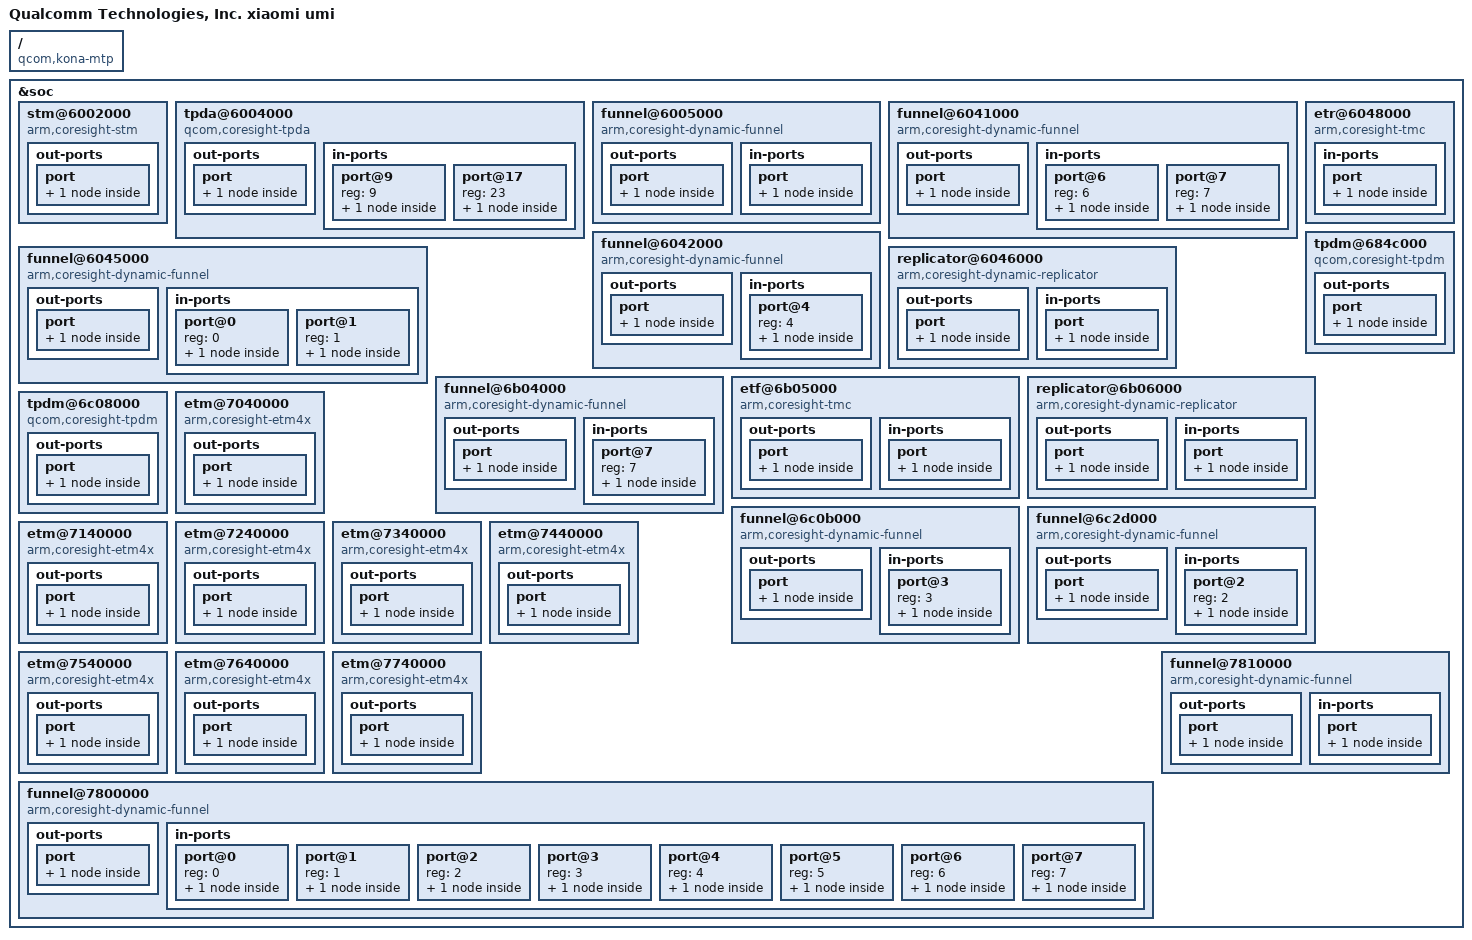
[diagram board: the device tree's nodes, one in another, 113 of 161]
/dts-v1/;
/plugin/;

#include <dt-bindings/clock/qcom,gcc-kona.h>
#include <dt-bindings/clock/qcom,camcc-kona.h>
#include <dt-bindings/clock/qcom,rpmh.h>
#include <dt-bindings/interrupt-controller/arm-gic.h>

#include "umi-sm8250.dtsi"
#include "umi-sm8250-camera-sensor-mtp.dtsi"
/ {
	model = "Qualcomm Technologies, Inc. xiaomi umi";
	compatible = "qcom,kona-mtp", "qcom,kona", "qcom,mtp";
	qcom,board-id = <43 0>;
};

&soc {
	/* CoreSight APSS ETM + funnels + sinks (from upstream sm8250.dtsi) */
	stm@6002000 {
		compatible = "arm,coresight-stm", "arm,primecell";
		reg = <0 0x06002000 0 0x1000>, <0 0x16280000 0 0x180000>;
		reg-names = "stm-base", "stm-stimulus-base";

		clocks = <&aoss_qmp>;
		clock-names = "apb_pclk";

		out-ports {
			port {
				stm_out: endpoint {
					remote-endpoint = <&funnel0_in7>;
				};
			};
		};
	};

	tpda@6004000 {
		compatible = "qcom,coresight-tpda", "arm,primecell";
		reg = <0 0x06004000 0 0x1000>;

		clocks = <&aoss_qmp>;
		clock-names = "apb_pclk";

		out-ports {
			port {
				tpda_out_funnel_qatb: endpoint {
					remote-endpoint = <&funnel_qatb_in_tpda>;
				};
			};
		};

		in-ports {
			#address-cells = <1>;
			#size-cells = <0>;

			port@9 {
				reg = <9>;
				tpda_9_in_tpdm_mm: endpoint {
					remote-endpoint = <&tpdm_mm_out_tpda9>;
				};
			};

			port@17 {
				reg = <23>;
				tpda_23_in_tpdm_prng: endpoint {
					remote-endpoint = <&tpdm_prng_out_tpda_23>;
				};
			};
		};
	};

	funnel@6005000 {
		compatible = "arm,coresight-dynamic-funnel", "arm,primecell";
		reg = <0 0x06005000 0 0x1000>;

		clocks = <&aoss_qmp>;
		clock-names = "apb_pclk";

		out-ports {
			port {
				funnel_qatb_out_funnel_in0: endpoint {
					remote-endpoint = <&funnel_in0_in_funnel_qatb>;
				};
			};
		};

		in-ports {
			port {
				funnel_qatb_in_tpda: endpoint {
					remote-endpoint = <&tpda_out_funnel_qatb>;
				};
			};
		};
	};

	funnel@6041000 {
		compatible = "arm,coresight-dynamic-funnel", "arm,primecell";
		reg = <0 0x06041000 0 0x1000>;

		clocks = <&aoss_qmp>;
		clock-names = "apb_pclk";

		out-ports {
			port {
				funnel_in0_out_funnel_merg: endpoint {
					remote-endpoint = <&funnel_merg_in_funnel_in0>;
				};
			};
		};

		in-ports {
			#address-cells = <1>;
			#size-cells = <0>;

			port@6 {
				reg = <6>;
				funnel_in0_in_funnel_qatb: endpoint {
					remote-endpoint = <&funnel_qatb_out_funnel_in0>;
				};
			};

			port@7 {
				reg = <7>;
				funnel0_in7: endpoint {
					remote-endpoint = <&stm_out>;
				};
			};
		};
	};

	funnel@6042000 {
		compatible = "arm,coresight-dynamic-funnel", "arm,primecell";
		reg = <0 0x06042000 0 0x1000>;

		clocks = <&aoss_qmp>;
		clock-names = "apb_pclk";

		out-ports {
			port {
				funnel_in1_out_funnel_merg: endpoint {
					remote-endpoint = <&funnel_merg_in_funnel_in1>;
				};
			};
		};

		in-ports {
			#address-cells = <1>;
			#size-cells = <0>;

			port@4 {
				reg = <4>;
				funnel_in1_in_funnel_apss_merg: endpoint {
					remote-endpoint = <&funnel_apss_merg_out_funnel_in1>;
				};
			};
		};
	};

	funnel@6045000 {
		compatible = "arm,coresight-dynamic-funnel", "arm,primecell";
		reg = <0 0x06045000 0 0x1000>;

		clocks = <&aoss_qmp>;
		clock-names = "apb_pclk";

		out-ports {
			port {
				funnel_merg_out_funnel_swao: endpoint {
					remote-endpoint = <&funnel_swao_in_funnel_merg>;
				};
			};
		};

		in-ports {
			#address-cells = <1>;
			#size-cells = <0>;

			port@0 {
				reg = <0>;
				funnel_merg_in_funnel_in0: endpoint {
					remote-endpoint = <&funnel_in0_out_funnel_merg>;
				};
			};

			port@1 {
				reg = <1>;
				funnel_merg_in_funnel_in1: endpoint {
					remote-endpoint = <&funnel_in1_out_funnel_merg>;
				};
			};
		};
	};

	replicator@6046000 {
		compatible = "arm,coresight-dynamic-replicator", "arm,primecell";
		reg = <0 0x06046000 0 0x1000>;

		clocks = <&aoss_qmp>;
		clock-names = "apb_pclk";

		out-ports {
			port {
				replicator_out: endpoint {
					remote-endpoint = <&etr_in>;
				};
			};
		};

		in-ports {
			port {
				replicator_cx_in_swao_out: endpoint {
					remote-endpoint = <&replicator_swao_out_cx_in>;
				};
			};
		};
	};

	etr@6048000 {
		compatible = "arm,coresight-tmc", "arm,primecell";
		reg = <0 0x06048000 0 0x1000>;

		clocks = <&aoss_qmp>;
		clock-names = "apb_pclk";
		arm,scatter-gather;

		in-ports {
			port {
				etr_in: endpoint {
					remote-endpoint = <&replicator_out>;
				};
			};
		};
	};

	tpdm@684c000 {
		compatible = "qcom,coresight-tpdm", "arm,primecell";
		reg = <0 0x0684c000 0 0x1000>;

		clocks = <&aoss_qmp>;
		clock-names = "apb_pclk";

		out-ports {
			port {
				tpdm_prng_out_tpda_23: endpoint {
					remote-endpoint = <&tpda_23_in_tpdm_prng>;
				};
			};
		};
	};

	funnel@6b04000 {
		compatible = "arm,coresight-dynamic-funnel", "arm,primecell";
		arm,primecell-periphid = <0x000bb908>;

		reg = <0 0x06b04000 0 0x1000>;

		clocks = <&aoss_qmp>;
		clock-names = "apb_pclk";

		out-ports {
			port {
				funnel_swao_out_etf: endpoint {
					remote-endpoint = <&etf_in_funnel_swao_out>;
				};
			};
		};

		in-ports {
			#address-cells = <1>;
			#size-cells = <0>;

			port@7 {
				reg = <7>;
				funnel_swao_in_funnel_merg: endpoint {
					remote-endpoint = <&funnel_merg_out_funnel_swao>;
				};
			};
		};
	};

	etf@6b05000 {
		compatible = "arm,coresight-tmc", "arm,primecell";
		reg = <0 0x06b05000 0 0x1000>;

		clocks = <&aoss_qmp>;
		clock-names = "apb_pclk";

		out-ports {
			port {
				etf_out: endpoint {
					remote-endpoint = <&replicator_in>;
				};
			};
		};

		in-ports {
			port {
				etf_in_funnel_swao_out: endpoint {
					remote-endpoint = <&funnel_swao_out_etf>;
				};
			};
		};
	};

	replicator@6b06000 {
		compatible = "arm,coresight-dynamic-replicator", "arm,primecell";
		reg = <0 0x06b06000 0 0x1000>;

		clocks = <&aoss_qmp>;
		clock-names = "apb_pclk";

		out-ports {
			port {
				replicator_swao_out_cx_in: endpoint {
					remote-endpoint = <&replicator_cx_in_swao_out>;
				};
			};
		};

		in-ports {
			port {
				replicator_in: endpoint {
					remote-endpoint = <&etf_out>;
				};
			};
		};
	};

	tpdm@6c08000 {
		compatible = "qcom,coresight-tpdm", "arm,primecell";
		reg = <0 0x06c08000 0 0x1000>;

		clocks = <&aoss_qmp>;
		clock-names = "apb_pclk";

		out-ports {
			port {
				tpdm_mm_out_funnel_dl_mm: endpoint {
					remote-endpoint = <&funnel_dl_mm_in_tpdm_mm>;
				};
			};
		};
	};

	funnel@6c0b000 {
		compatible = "arm,coresight-dynamic-funnel", "arm,primecell";
		reg = <0 0x06c0b000 0 0x1000>;

		clocks = <&aoss_qmp>;
		clock-names = "apb_pclk";

		out-ports {
			port {
				funnel_dl_mm_out_funnel_dl_center: endpoint {
					remote-endpoint = <&funnel_dl_center_in_funnel_dl_mm>;
				};
			};
		};

		in-ports {
			#address-cells = <1>;
			#size-cells = <0>;

			port@3 {
				reg = <3>;
				funnel_dl_mm_in_tpdm_mm: endpoint {
					remote-endpoint = <&tpdm_mm_out_funnel_dl_mm>;
				};
			};
		};
	};

	funnel@6c2d000 {
		compatible = "arm,coresight-dynamic-funnel", "arm,primecell";
		reg = <0 0x06c2d000 0 0x1000>;

		clocks = <&aoss_qmp>;
		clock-names = "apb_pclk";

		out-ports {
			port {
				tpdm_mm_out_tpda9: endpoint {
					remote-endpoint = <&tpda_9_in_tpdm_mm>;
				};
			};
		};

		in-ports {
			#address-cells = <1>;
			#size-cells = <0>;

			port@2 {
				reg = <2>;
				funnel_dl_center_in_funnel_dl_mm: endpoint {
					remote-endpoint = <&funnel_dl_mm_out_funnel_dl_center>;
				};
			};
		};
	};

	etm@7040000 {
		compatible = "arm,coresight-etm4x", "arm,primecell";
		reg = <0 0x07040000 0 0x1000>;
		cpu = <&cpu0>;
		clocks = <&aoss_qmp>;
		clock-names = "apb_pclk";
		arm,coresight-loses-context-with-cpu;

		out-ports {
			port {
				etm0_out: endpoint {
					remote-endpoint = <&apss_funnel_in0>;
				};
			};
		};
	};

	etm@7140000 {
		compatible = "arm,coresight-etm4x", "arm,primecell";
		reg = <0 0x07140000 0 0x1000>;
		cpu = <&cpu1>;
		clocks = <&aoss_qmp>;
		clock-names = "apb_pclk";
		arm,coresight-loses-context-with-cpu;

		out-ports {
			port {
				etm1_out: endpoint {
					remote-endpoint = <&apss_funnel_in1>;
				};
			};
		};
	};

	etm@7240000 {
		compatible = "arm,coresight-etm4x", "arm,primecell";
		reg = <0 0x07240000 0 0x1000>;
		cpu = <&cpu2>;
		clocks = <&aoss_qmp>;
		clock-names = "apb_pclk";
		arm,coresight-loses-context-with-cpu;

		out-ports {
			port {
				etm2_out: endpoint {
					remote-endpoint = <&apss_funnel_in2>;
				};
			};
		};
	};

	etm@7340000 {
		compatible = "arm,coresight-etm4x", "arm,primecell";
		reg = <0 0x07340000 0 0x1000>;
		cpu = <&cpu3>;
		clocks = <&aoss_qmp>;
		clock-names = "apb_pclk";
		arm,coresight-loses-context-with-cpu;

		out-ports {
			port {
				etm3_out: endpoint {
					remote-endpoint = <&apss_funnel_in3>;
				};
			};
		};
	};

	etm@7440000 {
		compatible = "arm,coresight-etm4x", "arm,primecell";
		reg = <0 0x07440000 0 0x1000>;
		cpu = <&cpu4>;
		clocks = <&aoss_qmp>;
		clock-names = "apb_pclk";
		arm,coresight-loses-context-with-cpu;

		out-ports {
			port {
				etm4_out: endpoint {
					remote-endpoint = <&apss_funnel_in4>;
				};
			};
		};
	};

	etm@7540000 {
		compatible = "arm,coresight-etm4x", "arm,primecell";
		reg = <0 0x07540000 0 0x1000>;
		cpu = <&cpu5>;
		clocks = <&aoss_qmp>;
		clock-names = "apb_pclk";
		arm,coresight-loses-context-with-cpu;

		out-ports {
			port {
				etm5_out: endpoint {
					remote-endpoint = <&apss_funnel_in5>;
				};
			};
		};
	};

	etm@7640000 {
		compatible = "arm,coresight-etm4x", "arm,primecell";
		reg = <0 0x07640000 0 0x1000>;
		cpu = <&cpu6>;
		clocks = <&aoss_qmp>;
		clock-names = "apb_pclk";
		arm,coresight-loses-context-with-cpu;

		out-ports {
			port {
				etm6_out: endpoint {
					remote-endpoint = <&apss_funnel_in6>;
				};
			};
		};
	};

	etm@7740000 {
		compatible = "arm,coresight-etm4x", "arm,primecell";
		reg = <0 0x07740000 0 0x1000>;
		cpu = <&cpu7>;
		clocks = <&aoss_qmp>;
		clock-names = "apb_pclk";
		arm,coresight-loses-context-with-cpu;

		out-ports {
			port {
				etm7_out: endpoint {
					remote-endpoint = <&apss_funnel_in7>;
				};
			};
		};
	};

	funnel@7800000 {
		compatible = "arm,coresight-dynamic-funnel", "arm,primecell";
		reg = <0 0x07800000 0 0x1000>;

		clocks = <&aoss_qmp>;
		clock-names = "apb_pclk";

		out-ports {
			port {
				funnel_apss_out_funnel_apss_merg: endpoint {
					remote-endpoint = <&funnel_apss_merg_in_funnel_apss>;
				};
			};
		};

		in-ports {
			#address-cells = <1>;
			#size-cells = <0>;

			port@0 {
				reg = <0>;
				apss_funnel_in0: endpoint {
					remote-endpoint = <&etm0_out>;
				};
			};

			port@1 {
				reg = <1>;
				apss_funnel_in1: endpoint {
					remote-endpoint = <&etm1_out>;
				};
			};

			port@2 {
				reg = <2>;
				apss_funnel_in2: endpoint {
					remote-endpoint = <&etm2_out>;
				};
			};

			port@3 {
				reg = <3>;
				apss_funnel_in3: endpoint {
					remote-endpoint = <&etm3_out>;
				};
			};

			port@4 {
				reg = <4>;
				apss_funnel_in4: endpoint {
					remote-endpoint = <&etm4_out>;
				};
			};

			port@5 {
				reg = <5>;
				apss_funnel_in5: endpoint {
					remote-endpoint = <&etm5_out>;
				};
			};

			port@6 {
				reg = <6>;
				apss_funnel_in6: endpoint {
					remote-endpoint = <&etm6_out>;
				};
			};

			port@7 {
				reg = <7>;
				apss_funnel_in7: endpoint {
					remote-endpoint = <&etm7_out>;
				};
			};
		};
	};

	funnel@7810000 {
		compatible = "arm,coresight-dynamic-funnel", "arm,primecell";
		reg = <0 0x07810000 0 0x1000>;

		clocks = <&aoss_qmp>;
		clock-names = "apb_pclk";

		out-ports {
			port {
				funnel_apss_merg_out_funnel_in1: endpoint {
					remote-endpoint = <&funnel_in1_in_funnel_apss_merg>;
				};
			};
		};

		in-ports {
			port {
				funnel_apss_merg_in_funnel_apss: endpoint {
					remote-endpoint = <&funnel_apss_out_funnel_apss_merg>;
				};
			};
		};
	};
};
